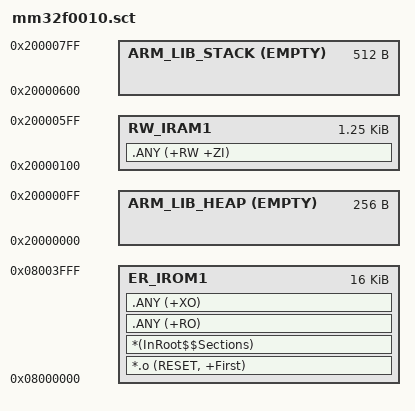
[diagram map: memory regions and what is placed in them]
LR_IROM1 0x08000000 0x00004000  {    ; load region size_region
  ER_IROM1 0x08000000 0x00004000  {  ; load address = execution address
   *.o (RESET, +First)
   *(InRoot$$Sections)
   .ANY (+RO)
   .ANY (+XO)
  }
  RW_IRAM1 0x20000100 0x00000500  {  ; RW data
   .ANY (+RW +ZI)
  }
  ARM_LIB_HEAP  0x20000000 EMPTY  0x00000100   {}
  ARM_LIB_STACK 0x20000800 EMPTY -0x00000200   {}
}

